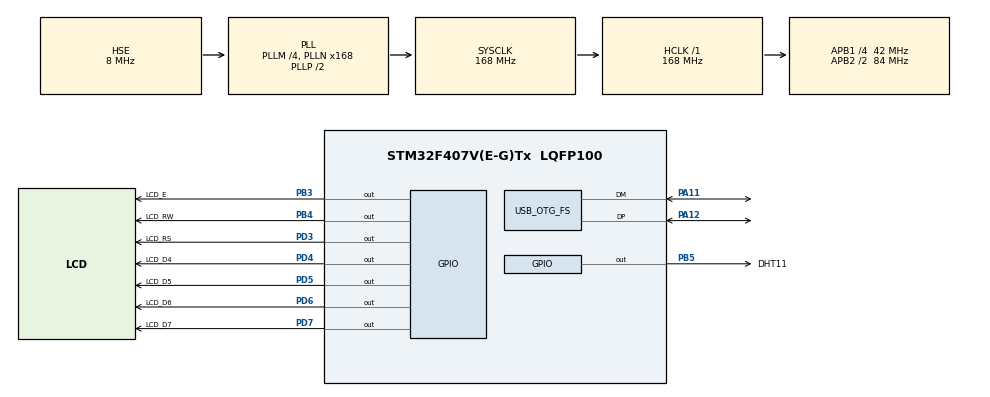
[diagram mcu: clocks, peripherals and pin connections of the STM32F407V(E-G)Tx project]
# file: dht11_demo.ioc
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Mcu.Family=STM32F4
Mcu.Name=STM32F407V(E-G)Tx
Mcu.Package=LQFP100
NVIC.OTG_FS_IRQn=true\:0\:0\:false\:false\:true\:false\:true
NVIC.PriorityGroup=NVIC_PRIORITYGROUP_4
PA11.Mode=Device_Only
PA11.Signal=USB_OTG_FS_DM
PA12.Mode=Device_Only
PA12.Signal=USB_OTG_FS_DP
PA13.Mode=Serial_Wire
PA13.Signal=SYS_JTMS-SWDIO
PA14.Mode=Serial_Wire
PA14.Signal=SYS_JTCK-SWCLK
PB3.GPIO_Label=LCD_E
PB3.Signal=GPIO_Output
PB4.GPIO_Label=LCD_RW
PB4.Signal=GPIO_Output
PB5.GPIO_Label=DHT11
PB5.Signal=GPIO_Output
PD3.GPIO_Label=LCD_RS
PD3.Signal=GPIO_Output
PD4.GPIO_Label=LCD_D4
PD4.Signal=GPIO_Output
PD5.GPIO_Label=LCD_D5
PD5.Signal=GPIO_Output
PD6.GPIO_Label=LCD_D6
PD6.Signal=GPIO_Output
PD7.GPIO_Label=LCD_D7
PD7.Signal=GPIO_Output
PH0-OSC_IN.Mode=HSE-External-Oscillator
PH0-OSC_IN.Signal=RCC_OSC_IN
PH1-OSC_OUT.Mode=HSE-External-Oscillator
PH1-OSC_OUT.Signal=RCC_OSC_OUT
ProjectManager.HeapSize=0x600
ProjectManager.StackSize=0x400
ProjectManager.TargetToolchain=MDK-ARM V5
RCC.48MHZClocksFreq_Value=48000000
RCC.AHBFreq_Value=168000000
RCC.APB1CLKDivider=RCC_HCLK_DIV4
RCC.APB1Freq_Value=42000000
RCC.APB1TimFreq_Value=84000000
RCC.APB2CLKDivider=RCC_HCLK_DIV2
RCC.APB2Freq_Value=84000000
RCC.APB2TimFreq_Value=168000000
RCC.CortexFreq_Value=168000000
RCC.HCLKFreq_Value=168000000
RCC.HSE_VALUE=8000000
RCC.HSI_VALUE=16000000
RCC.LSE_VALUE=32768
RCC.PLLM=4
RCC.PLLN=168
RCC.PLLQ=7
RCC.SYSCLKFreq_VALUE=168000000
RCC.SYSCLKSource=RCC_SYSCLKSOURCE_PLLCLK
RCC.VCOOutputFreq_Value=336000000
USB_DEVICE.CLASS_NAME_FS=CDC
USB_DEVICE.VirtualMode-CDC_FS=Cdc
USB_DEVICE.VirtualModeFS=Cdc_FS
USB_OTG_FS.VirtualMode=Device_Only
VP_FATFS_VS_Generic.Mode=User_defined
VP_TIM2_VS_ClockSourceINT.Mode=Internal
VP_USB_DEVICE_VS_USB_DEVICE_CDC_FS.Mode=CDC_FS
board=custom

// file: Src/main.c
/* USER CODE BEGIN Header */
/**
  ******************************************************************************
  * @file           : main.c
  * @brief          : Main program body
  ******************************************************************************
  * This notice applies to any and all portions of this file
  * that are not between comment pairs USER CODE BEGIN and
  * USER CODE END. Other portions of this file, whether
  * inserted by the user or by software development tools
  * are owned by their respective copyright owners.
  *
  * Copyright (c) 2019 STMicroelectronics International N.V.
  * All rights reserved.
  *
  * Redistribution and use in source and binary forms, with or without
  * modification, are permitted, provided that the following conditions are met:
  *
  * 1. Redistribution of source code must retain the above copyright notice,
  *    this list of conditions and the following disclaimer.
  * 2. Redistributions in binary form must reproduce the above copyright notice,
  *    this list of conditions and the following disclaimer in the documentation
  *    and/or other materials provided with the distribution.
  * 3. Neither the name of STMicroelectronics nor the names of other
  *    contributors to this software may be used to endorse or promote products
  *    derived from this software without specific written permission.
  * 4. This software, including modifications and/or derivative works of this
  *    software, must execute solely and exclusively on microcontroller or
  *    microprocessor devices manufactured by or for STMicroelectronics.
  * 5. Redistribution and use of this software other than as permitted under
  *    this license is void and will automatically terminate your rights under
  *    this license.
  *
  * THIS SOFTWARE IS PROVIDED BY STMICROELECTRONICS AND CONTRIBUTORS "AS IS"
  * AND ANY EXPRESS, IMPLIED OR STATUTORY WARRANTIES, INCLUDING, BUT NOT
  * LIMITED TO, THE IMPLIED WARRANTIES OF MERCHANTABILITY, FITNESS FOR A
  * PARTICULAR PURPOSE AND NON-INFRINGEMENT OF THIRD PARTY INTELLECTUAL PROPERTY
  * RIGHTS ARE DISCLAIMED TO THE FULLEST EXTENT PERMITTED BY LAW. IN NO EVENT
  * SHALL STMICROELECTRONICS OR CONTRIBUTORS BE LIABLE FOR ANY DIRECT, INDIRECT,
  * INCIDENTAL, SPECIAL, EXEMPLARY, OR CONSEQUENTIAL DAMAGES (INCLUDING, BUT NOT
  * LIMITED TO, PROCUREMENT OF SUBSTITUTE GOODS OR SERVICES; LOSS OF USE, DATA,
  * OR PROFITS; OR BUSINESS INTERRUPTION) HOWEVER CAUSED AND ON ANY THEORY OF
  * LIABILITY, WHETHER IN CONTRACT, STRICT LIABILITY, OR TORT (INCLUDING
  * NEGLIGENCE OR OTHERWISE) ARISING IN ANY WAY OUT OF THE USE OF THIS SOFTWARE,
  * EVEN IF ADVISED OF THE POSSIBILITY OF SUCH DAMAGE.
  *
  ******************************************************************************
  */
/* USER CODE END Header */

#include "main.h"
#include "fatfs.h"
#include "usb_device.h"

/* USER CODE BEGIN Includes */
#include "LCD.h"
#include "dht11.h"
/* USER CODE END Includes */

TIM_HandleTypeDef htim2;

void SystemClock_Config(void);
static void MX_GPIO_Init(void);
static void MX_TIM2_Init(void);

/* USER CODE BEGIN 0 */
DHT11_Dev dht11;
/* USER CODE END 0 */

int main(void)
{

  /* MCU Configuration--------------------------------------------------------*/

  /* Reset of all peripherals, Initializes the Flash interface and the Systick. */
  HAL_Init();

  /* Configure the system clock */
  SystemClock_Config();

  /* Initialize all configured peripherals */
  MX_GPIO_Init();
  MX_FATFS_Init();
  MX_USB_DEVICE_Init();
  MX_TIM2_Init();
  /* USER CODE BEGIN 2 */
  LCD_Init();
  DHT11_Init(&dht11,TIM2,DHT11_GPIO_Port,DHT11_Pin);
  /* USER CODE END 2 */

  /* Infinite loop */
  /* USER CODE BEGIN WHILE */
  char rh[40];
  char temp[40];
  while (1)
  {
		DHT11_Read(&dht11);
    sprintf(rh,   "RH  : %d.%d%%", dht11.humidity, dht11.hum_float);
    sprintf(temp, "TEMP: %d.%d ", dht11.temparature, dht11.temp_float);
    LCD_Puts(0,0,rh);
    LCD_Puts(0,1,temp);
    /* USER CODE END WHILE */

  }
}

void SystemClock_Config(void)
{
  RCC_OscInitTypeDef RCC_OscInitStruct = {0};
  RCC_ClkInitTypeDef RCC_ClkInitStruct = {0};

  /** Configure the main internal regulator output voltage
  */
  __HAL_RCC_PWR_CLK_ENABLE();
  __HAL_PWR_VOLTAGESCALING_CONFIG(PWR_REGULATOR_VOLTAGE_SCALE1);
  /** Initializes the CPU, AHB and APB busses clocks
  */
  RCC_OscInitStruct.OscillatorType = RCC_OSCILLATORTYPE_HSE;
  RCC_OscInitStruct.HSEState = RCC_HSE_ON;
  RCC_OscInitStruct.PLL.PLLState = RCC_PLL_ON;
  RCC_OscInitStruct.PLL.PLLSource = RCC_PLLSOURCE_HSE;
  RCC_OscInitStruct.PLL.PLLM = 4;
  RCC_OscInitStruct.PLL.PLLN = 168;
  RCC_OscInitStruct.PLL.PLLP = RCC_PLLP_DIV2;
  RCC_OscInitStruct.PLL.PLLQ = 7;
  if (HAL_RCC_OscConfig(&RCC_OscInitStruct) != HAL_OK)
  {
    Error_Handler();
  }
  /** Initializes the CPU, AHB and APB busses clocks
  */
  RCC_ClkInitStruct.ClockType = RCC_CLOCKTYPE_HCLK|RCC_CLOCKTYPE_SYSCLK
                              |RCC_CLOCKTYPE_PCLK1|RCC_CLOCKTYPE_PCLK2;
  RCC_ClkInitStruct.SYSCLKSource = RCC_SYSCLKSOURCE_PLLCLK;
  RCC_ClkInitStruct.AHBCLKDivider = RCC_SYSCLK_DIV1;
  RCC_ClkInitStruct.APB1CLKDivider = RCC_HCLK_DIV4;
  RCC_ClkInitStruct.APB2CLKDivider = RCC_HCLK_DIV2;

  if (HAL_RCC_ClockConfig(&RCC_ClkInitStruct, FLASH_LATENCY_5) != HAL_OK)
  {
    Error_Handler();
  }
}

static void MX_TIM2_Init(void)
{

  TIM_ClockConfigTypeDef sClockSourceConfig = {0};
  TIM_MasterConfigTypeDef sMasterConfig = {0};

  htim2.Instance = TIM2;
  htim2.Init.Prescaler = 0;
  htim2.Init.CounterMode = TIM_COUNTERMODE_UP;
  htim2.Init.Period = 0;
  htim2.Init.ClockDivision = TIM_CLOCKDIVISION_DIV1;
  htim2.Init.AutoReloadPreload = TIM_AUTORELOAD_PRELOAD_DISABLE;
  if (HAL_TIM_Base_Init(&htim2) != HAL_OK)
  {
    Error_Handler();
  }
  sClockSourceConfig.ClockSource = TIM_CLOCKSOURCE_INTERNAL;
  if (HAL_TIM_ConfigClockSource(&htim2, &sClockSourceConfig) != HAL_OK)
  {
    Error_Handler();
  }
  sMasterConfig.MasterOutputTrigger = TIM_TRGO_RESET;
  sMasterConfig.MasterSlaveMode = TIM_MASTERSLAVEMODE_DISABLE;
  if (HAL_TIMEx_MasterConfigSynchronization(&htim2, &sMasterConfig) != HAL_OK)
  {
    Error_Handler();
  }

}

static void MX_GPIO_Init(void)
{
  GPIO_InitTypeDef GPIO_InitStruct = {0};

  /* GPIO Ports Clock Enable */
  __HAL_RCC_GPIOH_CLK_ENABLE();
  __HAL_RCC_GPIOA_CLK_ENABLE();
  __HAL_RCC_GPIOD_CLK_ENABLE();
  __HAL_RCC_GPIOB_CLK_ENABLE();

  /*Configure GPIO pin Output Level */
  HAL_GPIO_WritePin(GPIOD, LCD_RS_Pin|LCD_D4_Pin|LCD_D5_Pin|LCD_D6_Pin
                          |LCD_D7_Pin, GPIO_PIN_RESET);

  /*Configure GPIO pin Output Level */
  HAL_GPIO_WritePin(GPIOB, LCD_E_Pin|LCD_RW_Pin|DHT11_Pin, GPIO_PIN_RESET);

  /*Configure GPIO pins : LCD_RS_Pin LCD_D4_Pin LCD_D5_Pin LCD_D6_Pin
                           LCD_D7_Pin */
  GPIO_InitStruct.Pin = LCD_RS_Pin|LCD_D4_Pin|LCD_D5_Pin|LCD_D6_Pin
                          |LCD_D7_Pin;
  GPIO_InitStruct.Mode = GPIO_MODE_OUTPUT_PP;
  GPIO_InitStruct.Pull = GPIO_NOPULL;
  GPIO_InitStruct.Speed = GPIO_SPEED_FREQ_LOW;
  HAL_GPIO_Init(GPIOD, &GPIO_InitStruct);

  /*Configure GPIO pins : LCD_E_Pin LCD_RW_Pin DHT11_Pin */
  GPIO_InitStruct.Pin = LCD_E_Pin|LCD_RW_Pin|DHT11_Pin;
  GPIO_InitStruct.Mode = GPIO_MODE_OUTPUT_PP;
  GPIO_InitStruct.Pull = GPIO_NOPULL;
  GPIO_InitStruct.Speed = GPIO_SPEED_FREQ_LOW;
  HAL_GPIO_Init(GPIOB, &GPIO_InitStruct);

}

void Error_Handler(void)
{
}

/************************ (C) COPYRIGHT STMicroelectronics *****END OF FILE****/
